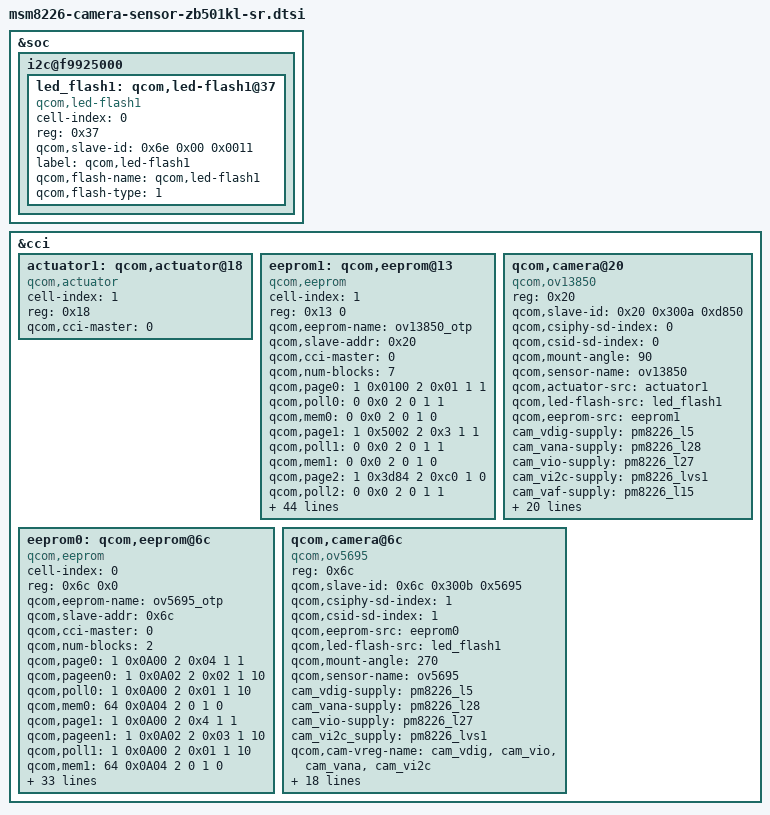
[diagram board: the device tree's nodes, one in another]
/*
 * Copyright (c) 2013-2014, The Linux Foundation. All rights reserved.
 *
 * This program is free software; you can redistribute it and/or modify
 * it under the terms of the GNU General Public License version 2 and
 * only version 2 as published by the Free Software Foundation.
 *
 * This program is distributed in the hope that it will be useful,
 * but WITHOUT ANY WARRANTY; without even the implied warranty of
 * MERCHANTABILITY or FITNESS FOR A PARTICULAR PURPOSE.  See the
 * GNU General Public License for more details.
 */

// [5816][FlashLED][akenhsu] Porting LM3644TT Flash LED for ASUS 5816 20150911 BEGIN
// [5816][FlashLED]20150911 END

&soc {
	i2c@f9925000 {
		status = "ok";
		led_flash1: qcom,led-flash1@37 {
		cell-index = <0>;
		reg = <0x37>;
		qcom,slave-id = <0x6e 0x00 0x0011>;
		compatible = "qcom,led-flash1";
		label = "qcom,led-flash1";
		qcom,flash-name = "qcom,led-flash1";
		qcom,flash-type = <1>;
	 };
	};
};
&cci {
//[5816][Camera] Add Main Camera 13M/5M Driveer Person Liu 20150915 S
	actuator1: qcom,actuator@18 {
		cell-index = <1>;
		reg = <0x18>;
		compatible = "qcom,actuator";
		qcom,cci-master = <0>;
	};

eeprom1: qcom,eeprom@13{
	cell-index = <1>;
	reg = <0x13 0>;
	qcom,eeprom-name = "ov13850_otp";
	compatible = "qcom,eeprom";
	qcom,slave-addr = <0x20>;
	qcom,cci-master = <0>;
	qcom,num-blocks = <7>;
	qcom,page0 = <1 0x0100 2 0x01 1 1>;
	qcom,poll0 = <0 0x0 2 0 1 1>;
	qcom,mem0 = <0 0x0 2 0 1 0>;
	qcom,page1 = <1 0x5002 2 0x3 1 1>;
	qcom,poll1 = <0 0x0 2 0 1 1>;
	qcom,mem1 = <0 0x0 2 0 1 0>;
	qcom,page2 = <1 0x3d84 2 0xc0 1 0>;
	qcom,poll2 = <0 0x0 2 0 1 1>;
	qcom,mem2 = <0 0x0 2 0 1 0>;
	qcom,page3 = <1 0x3d88 2 0x7220 2 0>;
	qcom,poll3 = <0 0x0 2 0 1 1>;
	qcom,mem3 = <0 0x0 2 0 1 0>;
	qcom,page4 = <1 0x3d8a 2 0x73BE 2 0>;
	qcom,poll4 = <0 0x0 2 0 1 1>;
	qcom,mem4 = <0 0x0 2 0 1 0>;
	qcom,page5 = <1 0x3d81 2 0x01 1 15>;
	qcom,poll5 = <0 0x0 2 0 1 1>;
	qcom,mem5 = <415 0x7220 2 0 1 0>;
	qcom,page6 = <1 0x5002 2 0x1 1 1>;
	qcom,poll6 = <0 0x0 2 0 1 1>;
	qcom,mem6 = <0 0x0 2 0 1 0>;
	
		cam_vdig-supply = <&pm8226_l5>;
		cam_vana-supply = <&pm8226_l28>;
		cam_vio-supply = <&pm8226_l27>;		
		cam_vi2c-supply = <&pm8226_lvs1>;
		cam_vaf-supply = <&pm8226_l15>;
		qcom,cam-vreg-name = "cam_vdig", "cam_vio", "cam_vana","cam_vi2c",
			"cam_vaf";
		qcom,cam-vreg-type = <0 0 0  1 0>;
		qcom,cam-vreg-min-voltage =  <1200000 1800000 2850000 0 2800000>;
		qcom,cam-vreg-max-voltage = <1200000 1800000 2850000 0 2800000>;
		qcom,cam-vreg-op-mode = <200000 0 80000 0 100000>;
		
		qcom,gpio-no-mux = <0>;
			gpios = <&msmgpio 26 0>,
			<&msmgpio 28 0>; /*reset gpio*/
			//<&msmgpio 12 0>, /*CAM_1V8_EN   IOVDD*/
			//<&msmgpio 13 0>;  /*CAM_2V8_EN    AVDD*/
		qcom,gpio-reset = <1>;
		qcom,gpio-req-tbl-num = <0 1 >;
		qcom,gpio-req-tbl-flags = <1 0 >;		
		//qcom,gpio-vio = <2>;
		//qcom,gpio-vana = <3>;		
		//qcom,gpio-req-tbl-num = <0 1 2 3>;
		//qcom,gpio-req-tbl-flags = <1 0 0 0>;
		qcom,gpio-req-tbl-label = "CAMIF_MCLK",
			"CAM_RESET1";
			//"CAM_1V8_EN",
			//"CAM_2V8_EN";
			
	qcom,cam-power-seq-type = "sensor_vreg","sensor_clk","sensor_vreg", 
	"sensor_vreg","sensor_vreg", "sensor_vreg",
	"sensor_gpio", "sensor_gpio";
	    
	qcom,cam-power-seq-val = "cam_vi2c","sensor_cam_mclk","cam_vana", 
	"cam_vio", "cam_vdig", "cam_vaf",
	"sensor_gpio_reset", "sensor_gpio_reset";
	        
	qcom,cam-power-seq-cfg-val = <0 19200000 0 0  0 0 0 1>;
	qcom,cam-power-seq-delay = <2 10 1 1 1 1 5 10>;
	
	};
	
	
	qcom,camera@20 {
		compatible = "qcom,ov13850";
		reg = <0x20>;
		qcom,slave-id = <0x20 0x300a 0xd850>;
		qcom,csiphy-sd-index = <0>;
		qcom,csid-sd-index = <0>;
		qcom,mount-angle = <90>;
		qcom,sensor-name = "ov13850";
		qcom,actuator-src = <&actuator1>;
		qcom,led-flash-src = <&led_flash1>;
		qcom,eeprom-src = <&eeprom1>;
		
		cam_vdig-supply = <&pm8226_l5>;
		cam_vana-supply = <&pm8226_l28>;
		cam_vio-supply = <&pm8226_l27>;		
		cam_vi2c-supply = <&pm8226_lvs1>;
		cam_vaf-supply = <&pm8226_l15>;
		qcom,cam-vreg-name = "cam_vdig", "cam_vio", "cam_vana","cam_vi2c",
			"cam_vaf";
		qcom,cam-vreg-type = <0 0 0  1 0>;
		qcom,cam-vreg-min-voltage =  <1200000 1800000 2850000 0 2800000>;
		qcom,cam-vreg-max-voltage = <1200000 1800000 2850000 0 2800000>;
		qcom,cam-vreg-op-mode = <200000 0 80000 0 100000>;

		qcom,gpio-no-mux = <0>;
			gpios = <&msmgpio 26 0>,
			<&msmgpio 28 0>; /*reset gpio*/
			//<&msmgpio 12 0>, /*CAM_1V8_EN   IOVDD*/
			//<&msmgpio 13 0>;  /*CAM_2V8_EN    AVDD*/
		qcom,gpio-reset = <1>;
		qcom,gpio-req-tbl-num = <0 1 >;
		qcom,gpio-req-tbl-flags = <1 0 >;		
		//qcom,gpio-vio = <2>;
		//qcom,gpio-vana = <3>;		
		//qcom,gpio-req-tbl-num = <0 1 2 3>;
		//qcom,gpio-req-tbl-flags = <1 0 0 0>;
		qcom,gpio-req-tbl-label = "CAMIF_MCLK",
			"CAM_RESET1";
			//"CAM_1V8_EN",
			//"CAM_2V8_EN";

		qcom,csi-lane-assign = <0x4320>;
		qcom,csi-lane-mask = <0x1f>;
		qcom,sensor-position = <0>;
		qcom,sensor-mode = <1>;
		qcom,cci-master = <0>;
	};

//ASUS BSP Ryan +++ for ov5695 1-lane
	eeprom0: qcom,eeprom@6c {
		cell-index = <0>;
		reg = <0x6c 0x0>;
		qcom,eeprom-name = "ov5695_otp";
		compatible = "qcom,eeprom";
		qcom,slave-addr = <0x6c>;
		qcom,cci-master = <0>;
		qcom,num-blocks = <2>;

		qcom,page0 = <1 0x0A00 2 0x04 1 1>;
		qcom,pageen0 = <1 0x0A02 2 0x02 1 10>;
		qcom,poll0 = <1 0x0A00 2 0x01 1 10>;
		qcom,mem0 = <64 0x0A04 2 0 1 0>;

		qcom,page1 = <1 0x0A00 2 0x4 1 1>;
		qcom,pageen1 = <1 0x0A02 2 0x03 1 10>;
		qcom,poll1 = <1 0x0A00 2 0x01 1 10>;
		qcom,mem1 = <64 0x0A04 2 0 1 0>;

		qcom,mm-data-support;
		qcom,mm-data-compressed;
		qcom,mm-data-offset = <0>;
		qcom,mm-data-size = <0>;

		cam_vdig-supply = <&pm8226_l5>;
		cam_vio-supply = <&pm8226_lvs1>;
		qcom,cam-vreg-name = "cam_vdig", "cam_vio";
		qcom,cam-vreg-type = <0 1>;
		qcom,cam-vreg-min-voltage = <1200000 0>;
		qcom,cam-vreg-max-voltage = <1200000 0>;
		qcom,cam-vreg-op-mode = <200000 0>;
		qcom,gpio-no-mux = <0>;

		gpios = <&msmgpio 26 0>,
			<&msmgpio 37 0>,
			<&msmgpio 12 0>,
			<&msmgpio 13 0>;
		qcom,gpio-reset = <1>;
		qcom,gpio-vio = <2>;
		qcom,gpio-vana = <3>;
		qcom,gpio-req-tbl-num = <0 1 2 3>;
		qcom,gpio-req-tbl-flags = <1 0 0 0>;
		qcom,gpio-req-tbl-label = "CAMIF_MCLK",
			"CAM_RESET1",
			"CAM1_1V8_EN",
			"CAM1_2V8_EN";

		qcom,cam-power-seq-type = "sensor_vreg",
			"sensor_gpio", "sensor_gpio",
			"sensor_gpio", "sensor_gpio",
			"sensor_vreg","sensor_gpio",
			"sensor_gpio","sensor_clk","sensor_i2c_mux";
		qcom,cam-power-seq-val = "cam_vio",
			"sensor_gpio_vio","sensor_gpio_vio",
			"sensor_gpio_vana","sensor_gpio_vana",
			"cam_vdig","sensor_gpio_reset",
			"sensor_gpio_reset","sensor_cam_mclk","none";
		qcom,cam-power-seq-cfg-val = <0 0 1 0 1 0 0 1 24000000 0>;
		qcom,cam-power-seq-delay = <0 0 0 0 0 0 0 5 5 0>;
	};

qcom,camera@6c {
		compatible = "qcom,ov5695";
		reg = <0x6c>;
		qcom,slave-id = <0x6c 0x300b 0x5695>;
		qcom,csiphy-sd-index = <1>;
		qcom,csid-sd-index = <1>;
		qcom,eeprom-src = <&eeprom0>;
		qcom,led-flash-src = <&led_flash1>;		
		qcom,mount-angle = <270>;
		qcom,sensor-name = "ov5695";
		cam_vdig-supply = <&pm8226_l5>;
		cam_vana-supply = <&pm8226_l28>;
		cam_vio-supply = <&pm8226_l27>;
		cam_vi2c_supply = <&pm8226_lvs1>;
//		cam_vana-supply = <&pm8226_l19>;
//		cam_vio-supply = <&pm8226_lvs1>;
		qcom,cam-vreg-name = "cam_vdig", "cam_vio", "cam_vana", "cam_vi2c";
		qcom,cam-vreg-type = <0 0 0 1>;
		qcom,cam-vreg-min-voltage =  <1200000 1800000 2850000 0>;
		qcom,cam-vreg-max-voltage = <1200000 1800000 2850000 0>;
		qcom,cam-vreg-op-mode = <200000 0 80000 0>;
		qcom,gpio-no-mux = <0>;
		gpios = <&msmgpio 26 0>,
			<&msmgpio 37 0>;
			//<&msmgpio 12 0>,
			//<&msmgpio 13 0>;
		qcom,gpio-reset = <1>;
		qcom,gpio-req-tbl-num = <0 1>;
		qcom,gpio-req-tbl-flags = <1 0 >;
		//qcom,gpio-vio = <2>;
		//qcom,gpio-vana = <3>;
		//qcom,gpio-req-tbl-num = <0 1 2 3>;
		//qcom,gpio-req-tbl-flags = <1 0 0 0>;
		qcom,gpio-req-tbl-label = "CAMIF_MCLK",
			"CAM_RESET1";
			//"CAM1_1V8_EN",
			//"CAM1_2V8_EN";
		qcom,csi-lane-assign = <0x4320>;
		qcom,csi-lane-mask = <0x03>;
		qcom,sensor-position = <1>;
		qcom,sensor-mode = <0>;
		qcom,cci-master = <0>;
	};
//ASUS BSP Ryan --- for ov5695 1-lane
};

